AUTOSAR XML (schema 3.1.2)
package /Components/SWC_TqEM
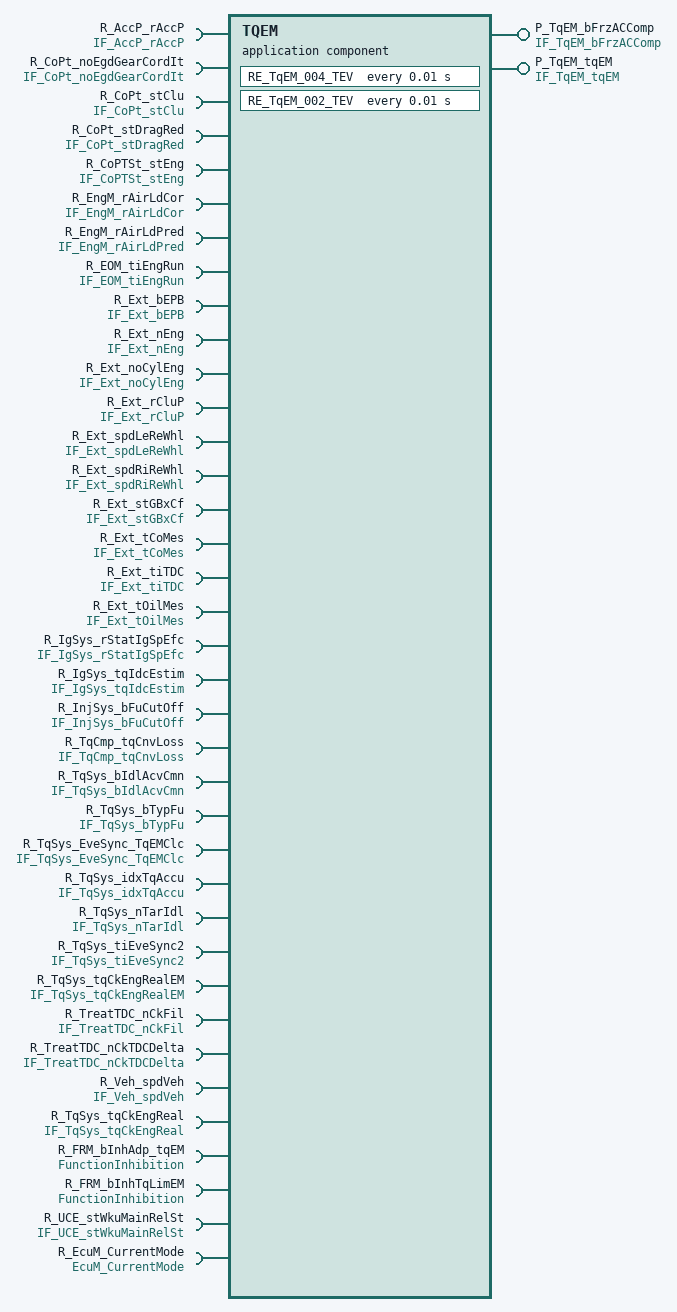
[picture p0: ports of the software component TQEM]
  application software component type TQEM
    35 x require port:
      R_AccP_rAccP: unqueued-receiver-com-spec{data-element=AccP_rAccP, init-value=ConstantValue, resync-time=0}, required-interface=IF_AccP_rAccP
      R_CoPt_noEgdGearCordIt: unqueued-receiver-com-spec{data-element=CoPt_noEgdGearCordIt, init-value=ConstantValue1, resync-time=0}, required-interface=IF_CoPt_noEgdGearCordIt
      R_CoPt_stClu: unqueued-receiver-com-spec{data-element=CoPt_stClu, init-value=CoPt_stClu_in, resync-time=0}, required-interface=IF_CoPt_stClu
      R_CoPt_stDragRed: unqueued-receiver-com-spec{data-element=CoPt_stDragRed, init-value=ConstantValue3, resync-time=0}, required-interface=IF_CoPt_stDragRed
      R_CoPTSt_stEng: unqueued-receiver-com-spec{data-element=CoPTSt_stEng, init-value=ConstantValue5, resync-time=0}, required-interface=IF_CoPTSt_stEng
      R_EngM_rAirLdCor: unqueued-receiver-com-spec{data-element=EngM_rAirLdCor, init-value=ConstantValue7, resync-time=0}, required-interface=IF_EngM_rAirLdCor
      R_EngM_rAirLdPred: unqueued-receiver-com-spec{data-element=EngM_rAirLdPred, init-value=ConstantValue9, resync-time=0}, required-interface=IF_EngM_rAirLdPred
      R_EOM_tiEngRun: unqueued-receiver-com-spec{data-element=EOM_tiEngRun, init-value=ConstantValue11, resync-time=0}, required-interface=IF_EOM_tiEngRun
      R_Ext_bEPB: unqueued-receiver-com-spec{data-element=Ext_bEPB, init-value=Ext_bEPB_in, resync-time=0}, required-interface=IF_Ext_bEPB
      R_Ext_nEng: unqueued-receiver-com-spec{data-element=Ext_nEng, init-value=ConstantValue13, resync-time=0}, required-interface=IF_Ext_nEng
      R_Ext_noCylEng: unqueued-receiver-com-spec{data-element=Ext_noCylEng, init-value=ConstantValue15, resync-time=0}, required-interface=IF_Ext_noCylEng
      R_Ext_rCluP: unqueued-receiver-com-spec{data-element=Ext_rCluP, init-value=Ext_rCluP_in, resync-time=0}, required-interface=IF_Ext_rCluP
      R_Ext_spdLeReWhl: unqueued-receiver-com-spec{data-element=Ext_spdLeReWhl, init-value=Ext_spdLeReWhl_in, resync-time=0}, required-interface=IF_Ext_spdLeReWhl
      R_Ext_spdRiReWhl: unqueued-receiver-com-spec{data-element=Ext_spdRiReWhl, init-value=Ext_spdRiReWhl_in, resync-time=0}, required-interface=IF_Ext_spdRiReWhl
      R_Ext_stGBxCf: unqueued-receiver-com-spec{data-element=Ext_stGBxCf, init-value=ConstantValue17, resync-time=0}, required-interface=IF_Ext_stGBxCf
      R_Ext_tCoMes: unqueued-receiver-com-spec{data-element=Ext_tCoMes, init-value=ConstantValue19, resync-time=0}, required-interface=IF_Ext_tCoMes
      R_Ext_tiTDC: unqueued-receiver-com-spec{data-element=Ext_tiTDC, init-value=ConstantValue21, resync-time=0}, required-interface=IF_Ext_tiTDC
      R_Ext_tOilMes: unqueued-receiver-com-spec{data-element=Ext_tOilMes, init-value=ConstantValue23, resync-time=0}, required-interface=IF_Ext_tOilMes
      R_IgSys_rStatIgSpEfc: unqueued-receiver-com-spec{data-element=IgSys_rStatIgSpEfc, init-value=ConstantValue25, resync-time=0}, required-interface=IF_IgSys_rStatIgSpEfc
      R_IgSys_tqIdcEstim: unqueued-receiver-com-spec{data-element=IgSys_tqIdcEstim, init-value=ConstantValue27, resync-time=0}, required-interface=IF_IgSys_tqIdcEstim
      R_InjSys_bFuCutOff: unqueued-receiver-com-spec{data-element=InjSys_bFuCutOff, init-value=ConstantValue29, resync-time=0}, required-interface=IF_InjSys_bFuCutOff
      R_TqCmp_tqCnvLoss: unqueued-receiver-com-spec{data-element=TqCmp_tqCnvLoss, init-value=ConstantValue31, resync-time=0}, required-interface=IF_TqCmp_tqCnvLoss
      R_TqSys_bIdlAcvCmn: unqueued-receiver-com-spec{data-element=TqSys_bIdlAcvCmn, init-value=ConstantValue33, resync-time=0}, required-interface=IF_TqSys_bIdlAcvCmn
      R_TqSys_bTypFu: unqueued-receiver-com-spec{data-element=TqSys_bTypFu, init-value=ConstantValue35, resync-time=0}, required-interface=IF_TqSys_bTypFu
      R_TqSys_EveSync_TqEMClc: unqueued-receiver-com-spec{data-element=TqSys_EveSync_TqEMClc, init-value=TqSys_EveSync_TqEMClc_in, resync-time=0}, required-interface=IF_TqSys_EveSync_TqEMClc
      R_TqSys_idxTqAccu: unqueued-receiver-com-spec{data-element=TqSys_idxTqAccu, init-value=ConstantValue37, resync-time=0}, required-interface=IF_TqSys_idxTqAccu
      R_TqSys_nTarIdl: unqueued-receiver-com-spec{data-element=TqSys_nTarIdl, init-value=ConstantValue39, resync-time=0}, required-interface=IF_TqSys_nTarIdl
      R_TqSys_tiEveSync2: unqueued-receiver-com-spec{data-element=TqSys_tiEveSync2, init-value=TqSys_tiEveSync2_in, resync-time=0}, required-interface=IF_TqSys_tiEveSync2
      R_TqSys_tqCkEngRealEM: unqueued-receiver-com-spec{data-element=TqSys_tqCkEngRealEM, init-value=ConstantValue41, resync-time=0}, required-interface=IF_TqSys_tqCkEngRealEM
      R_TreatTDC_nCkFil: unqueued-receiver-com-spec{data-element=TreatTDC_nCkFil, init-value=ConstantValue43, resync-time=0}, required-interface=IF_TreatTDC_nCkFil
      R_TreatTDC_nCkTDCDelta: unqueued-receiver-com-spec{data-element=TreatTDC_nCkTDCDelta, init-value=ConstantValue45, resync-time=0}, required-interface=IF_TreatTDC_nCkTDCDelta
      R_Veh_spdVeh: unqueued-receiver-com-spec{data-element=Veh_spdVeh, init-value=ConstantValue47, resync-time=0}, required-interface=IF_Veh_spdVeh
      R_TqSys_tqCkEngReal: unqueued-receiver-com-spec{data-element=TqSys_tqCkEngReal, init-value=ConstantValue49, resync-time=0}, required-interface=IF_TqSys_tqCkEngReal
      R_FRM_bInhAdp_tqEM: required-interface=FunctionInhibition
      R_FRM_bInhTqLimEM: required-interface=FunctionInhibition
    provide port P_TqEM_bFrzACComp: unqueued-sender-com-spec{data-element=TqEM_bFrzACComp, can-invalidate=false, init-value=ConstantValue51}, provided-interface=IF_TqEM_bFrzACComp
    provide port P_TqEM_tqEM: unqueued-sender-com-spec{data-element=TqEM_tqEM, can-invalidate=false, init-value=TqEM_tqEM_out}, provided-interface=IF_TqEM_tqEM
    require port R_UCE_stWkuMainRelSt: required-interface=IF_UCE_stWkuMainRelSt
    require port R_EcuM_CurrentMode: required-interface=EcuM_CurrentMode
  46 x constant specification:
    ConstantValue
      value:
        integer literal ConstantValue: type=DT_AccP_rAccP, value=0
    ConstantValue1
      value:
        integer literal ConstantValue1: type=DT_CoPt_noEgdGearCordIt, value=0
    ConstantValue11
      value:
        integer literal ConstantValue11: type=DT_EOM_tiEngRun, value=0
    ConstantValue13
      value:
        integer literal ConstantValue13: type=DT_Ext_nEng, value=0
    ConstantValue15
      value:
        integer literal ConstantValue15: type=DT_Ext_noCylEng, value=1
    ConstantValue17
      value:
        integer literal ConstantValue17: type=DT_Ext_stGBxCf, value=0
    ConstantValue19
      value:
        integer literal ConstantValue19: type=DT_Ext_tCoMes, value=20
    ConstantValue21
      value:
        integer literal ConstantValue21: type=DT_Ext_tiTDC, value=100
    ConstantValue23
      value:
        integer literal ConstantValue23: type=DT_Ext_tOilMes, value=0
    ConstantValue25
      value:
        integer literal ConstantValue25: type=DT_IgSys_rStatIgSpEfc, value=0
    ConstantValue27
      value:
        integer literal ConstantValue27: type=DT_IgSys_tqIdcEstim, value=0
    ConstantValue29
      value:
        boolean literal ConstantValue29: type=DT_InjSys_bFuCutOff, value=false
    ConstantValue3
      value:
        integer literal ConstantValue3: type=DT_CoPt_stDragRed, value=0
    ConstantValue31
      value:
        integer literal ConstantValue31: type=DT_TqCmp_tqCnvLoss, value=0
    ConstantValue33
      value:
        boolean literal ConstantValue33: type=DT_TqSys_bIdlAcvCmn, value=true
    ConstantValue35
      value:
        boolean literal ConstantValue35: type=DT_TqSys_bTypFu, value=false
    ConstantValue37
      value:
        integer literal ConstantValue37: type=DT_TqSys_idxTqAccu, value=1
    ConstantValue39
      value:
        integer literal ConstantValue39: type=DT_TqSys_nTarIdl, value=0
    ConstantValue41
      value:
        integer literal ConstantValue41: type=DT_TqSys_tqCkEngRealEM, value=0
    ConstantValue43
      value:
        integer literal ConstantValue43: type=DT_TreatTDC_nCkFil, value=0
    ConstantValue45
      value:
        integer literal ConstantValue45: type=DT_TreatTDC_nCkTDCDelta, value=0
    ConstantValue47
      value:
        integer literal ConstantValue47: type=DT_Veh_spdVeh, value=0
    ConstantValue49
      value:
        integer literal ConstantValue49: type=DT_TqSys_tqCkEngReal, value=0
    ConstantValue5
      value:
        integer literal ConstantValue5: type=DT_CoPTSt_stEng, value=1
    ConstantValue51
      value:
        boolean literal ConstantValue51: type=DT_TqEM_bFrzACComp, value=false
    ConstantValue7
      value:
        integer literal ConstantValue7: type=DT_EngM_rAirLdCor, value=0
    ConstantValue9
      value:
        integer literal ConstantValue9: type=DT_EngM_rAirLdPred, value=0
    CoPt_stClu_in
      value:
        integer literal CoPt_stClu_in: type=DT_CoPt_stClu, value=0
    Ext_bEPB_in
      value:
        boolean literal Ext_bEPB_in: type=DT_Ext_bEPB, value=false
    Ext_rCluP_in
      value:
        integer literal Ext_rCluP_in: type=DT_Ext_rCluP, value=0
    Ext_spdLeReWhl_in
      value:
        integer literal Ext_spdLeReWhl_in: type=DT_Ext_spdLeReWhl, value=0
    Ext_spdRiReWhl_in
      value:
        integer literal Ext_spdRiReWhl_in: type=DT_Ext_spdRiReWhl, value=0
    TqEM_bAuthClc_Cst
      value:
        boolean literal TqEM_bAuthClc_Cst: type=DT_TqEM_bAuthClc, value=false
    TqEM_bEnaAvr3Sync_Cst
      value:
        boolean literal TqEM_bEnaAvr3Sync_Cst: type=DT_TqEM_bEnaAvr3Sync, value=false
    TqEM_bEnaAvr4Sync_Cst
      value:
        boolean literal TqEM_bEnaAvr4Sync_Cst: type=DT_TqEM_bEnaAvr4Sync, value=false
    TqEM_bEnaAvr6Sync_Cst
      value:
        boolean literal TqEM_bEnaAvr6Sync_Cst: type=DT_TqEM_bEnaAvr6Sync, value=false
    TqEM_EveSync_Cst
      value:
        boolean literal TqEM_EveSync_Cst: type=DT_TqEM_EveSync, value=false
    TqEM_facTEng_Cst
      value:
        integer literal TqEM_facTEng_Cst: type=DT_TqEM_facTEng, value=40
    TqEM_tiEveSync_Cst
      value:
        integer literal TqEM_tiEveSync_Cst: type=DT_TqEM_tiEveSync, value=0
    TqEM_tqAdp_Cst
      value:
        integer literal TqEM_tqAdp_Cst: type=DT_TqEM_tqAdp, value=0
    TqEM_tqAdpRaw_Cst
      value:
        integer literal TqEM_tqAdpRaw_Cst: type=DT_TqEM_tqAdpRaw, value=0
    TqEM_tqCkEngRealEM_Cst
      value:
        integer literal TqEM_tqCkEngRealEM_Cst: type=DT_TqEM_tqCkEngRealEM, value=0
    TqEM_tqEM_out
      value:
        integer literal TqEM_tqEM_out: type=DT_TqEM_tqEM, value=0
    TqEM_tqEMWiCutOff_Cst
      value:
        integer literal TqEM_tqEMWiCutOff_Cst: type=DT_TqEM_tqEMWiCutOff, value=0
    TqSys_EveSync_TqEMClc_in
      value:
        boolean literal TqSys_EveSync_TqEMClc_in: type=DT_TqSys_EveSync_TqEMClc, value=false
    TqSys_tiEveSync2_in
      value:
        integer literal TqSys_tiEveSync2_in: type=DT_TqSys_tiEveSync2, value=0
  internal behavior IB_TqEM: component=TQEM
    mode switch event EV_TqEM_001_MSE: start-on-event=RE_TqEM_001_MSE, activation=ENTRY, mode=R_EcuM_CurrentMode.currentMode.RUN
    timing event EV_TqEM_004_TEV: mode-dependency=dependent-on-mode=[R_UCE_stWkuMainRelSt.RCD_stWkuMainRelSt.PreMainWakeUp, R_UCE_stWkuMainRelSt.RCD_stWkuMainRelSt.PostMainWakeUp, R_UCE_stWkuMainRelSt.RCD_stWkuMainRelSt.Invalid], start-on-event=RE_TqEM_004_TEV, period=0.01
    data received event EV_TqEM_006_DRE: mode-dependency=dependent-on-mode=[R_UCE_stWkuMainRelSt.RCD_stWkuMainRelSt.PreMainWakeUp, R_UCE_stWkuMainRelSt.RCD_stWkuMainRelSt.PostMainWakeUp, R_UCE_stWkuMainRelSt.RCD_stWkuMainRelSt.Invalid], start-on-event=RE_TqEM_006_DRE, data=R_TqSys_EveSync_TqEMClc.TqSys_EveSync_TqEMClc
    timing event EV_TqEM_002_TEV: mode-dependency=dependent-on-mode=[R_UCE_stWkuMainRelSt.RCD_stWkuMainRelSt.PreMainWakeUp, R_UCE_stWkuMainRelSt.RCD_stWkuMainRelSt.PostMainWakeUp, R_UCE_stWkuMainRelSt.RCD_stWkuMainRelSt.Invalid], start-on-event=RE_TqEM_002_TEV, period=0.01
    11 x inter runnable variable, all with sw-calibration-access=READ-WRITE, communication-approach=EXPLICIT:
      TqEM_facTEng: type=DT_TqEM_facTEng, init-value=TqEM_facTEng_Cst
      TqEM_tqCkEngRealEM: type=DT_TqEM_tqCkEngRealEM, init-value=TqEM_tqCkEngRealEM_Cst
      TqEM_bAuthClc: type=DT_TqEM_bAuthClc, init-value=TqEM_bAuthClc_Cst
      TqEM_tqAdpRaw: type=DT_TqEM_tqAdpRaw, init-value=TqEM_tqAdpRaw_Cst
      TqEM_bEnaAvr3Sync: type=DT_TqEM_bEnaAvr3Sync, init-value=TqEM_bEnaAvr3Sync_Cst
      TqEM_bEnaAvr6Sync: type=DT_TqEM_bEnaAvr6Sync, init-value=TqEM_bEnaAvr6Sync_Cst
      TqEM_tiEveSync: type=DT_TqEM_tiEveSync, init-value=TqEM_tiEveSync_Cst
      TqEM_EveSync: type=DT_TqEM_EveSync, init-value=TqEM_EveSync_Cst
      TqEM_bEnaAvr4Sync: type=DT_TqEM_bEnaAvr4Sync, init-value=TqEM_bEnaAvr4Sync_Cst
      TqEM_tqEMWiCutOff: type=DT_TqEM_tqEMWiCutOff, init-value=TqEM_tqEMWiCutOff_Cst
      TqEM_tqAdp: type=DT_TqEM_tqAdp, init-value=TqEM_tqAdp_Cst
    4 x runnable:
      RE_TqEM_006_DRE: read-variable=[TqEM_bAuthClc, TqEM_facTEng, TqEM_EveSync, TqEM_tqAdp, TqEM_tiEveSync, TqEM_tqCkEngRealEM], written-variable=[TqEM_bEnaAvr6Sync, TqEM_tqEMWiCutOff, TqEM_tqAdpRaw, TqEM_bEnaAvr3Sync, TqEM_bEnaAvr4Sync]
        16 x data receive point:
          dr_TqSys_bTypFu: data-element=R_TqSys_bTypFu.TqSys_bTypFu
          dr_TqSys_idxTqAccu: data-element=R_TqSys_idxTqAccu.TqSys_idxTqAccu
          dr_TreatTDC_nCkFil: data-element=R_TreatTDC_nCkFil.TreatTDC_nCkFil
          dr_TreatTDC_nCkTDCDelta: data-element=R_TreatTDC_nCkTDCDelta.TreatTDC_nCkTDCDelta
          dr_Ext_tCoMes: data-element=R_Ext_tCoMes.Ext_tCoMes
          dr_AccP_rAccP: data-element=R_AccP_rAccP.AccP_rAccP
          dr_IgSys_rStatIgSpEfc: data-element=R_IgSys_rStatIgSpEfc.IgSys_rStatIgSpEfc
          dr_EngM_rAirLdCor: data-element=R_EngM_rAirLdCor.EngM_rAirLdCor
          dr_TqSys_nTarIdl: data-element=R_TqSys_nTarIdl.TqSys_nTarIdl
          dr_InjSys_bFuCutOff: data-element=R_InjSys_bFuCutOff.InjSys_bFuCutOff
          dr_EngM_rAirLdPred: data-element=R_EngM_rAirLdPred.EngM_rAirLdPred
          dr_EOM_tiEngRun: data-element=R_EOM_tiEngRun.EOM_tiEngRun
          dr_IgSys_tqIdcEstim: data-element=R_IgSys_tqIdcEstim.IgSys_tqIdcEstim
          dr_TqCmp_tqCnvLoss: data-element=R_TqCmp_tqCnvLoss.TqCmp_tqCnvLoss
          dr_Ext_nEng: data-element=R_Ext_nEng.Ext_nEng
          dr_Ext_noCylEng: data-element=R_Ext_noCylEng.Ext_noCylEng
      RE_TqEM_004_TEV: read-variable=[TqEM_tqAdpRaw, TqEM_bEnaAvr6Sync, TqEM_tqCkEngRealEM, TqEM_tqEMWiCutOff, TqEM_bEnaAvr4Sync, TqEM_bEnaAvr3Sync], written-variable=[TqEM_bAuthClc, TqEM_tqAdp, TqEM_facTEng]
        16 x data receive point:
          dr_CoPt_noEgdGearCordIt: data-element=R_CoPt_noEgdGearCordIt.CoPt_noEgdGearCordIt
          dr_Ext_nEng: data-element=R_Ext_nEng.Ext_nEng
          dr_Ext_tCoMes: data-element=R_Ext_tCoMes.Ext_tCoMes
          dr_CoPt_stDragRed: data-element=R_CoPt_stDragRed.CoPt_stDragRed
          dr_CoPTSt_stEng: data-element=R_CoPTSt_stEng.CoPTSt_stEng
          dr_TqSys_nTarIdl: data-element=R_TqSys_nTarIdl.TqSys_nTarIdl
          dr_CoPt_stClu: data-element=R_CoPt_stClu.CoPt_stClu
          dr_Ext_rCluP: data-element=R_Ext_rCluP.Ext_rCluP
          dr_Ext_tOilMes: data-element=R_Ext_tOilMes.Ext_tOilMes
          dr_Ext_stGBxCf: data-element=R_Ext_stGBxCf.Ext_stGBxCf
          dr_Ext_bEPB: data-element=R_Ext_bEPB.Ext_bEPB
          dr_AccP_rAccP: data-element=R_AccP_rAccP.AccP_rAccP
          dr_TqSys_bIdlAcvCmn: data-element=R_TqSys_bIdlAcvCmn.TqSys_bIdlAcvCmn
          dr_Ext_spdLeReWhl: data-element=R_Ext_spdLeReWhl.Ext_spdLeReWhl
          dr_Ext_spdRiReWhl: data-element=R_Ext_spdRiReWhl.Ext_spdRiReWhl
          dr_Veh_spdVeh: data-element=R_Veh_spdVeh.Veh_spdVeh
        data send point ds_TqEM_tqEM: data-element=P_TqEM_tqEM.TqEM_tqEM
        data send point ds_TqEM_bFrzACComp: data-element=P_TqEM_bFrzACComp.TqEM_bFrzACComp
        sync call ssp_FRM_bInhTqLimEM: operation=R_FRM_bInhTqLimEM.GetFunctionPermission
        sync call ssp_FRM_bInhAdp_tqEM: operation=R_FRM_bInhAdp_tqEM.GetFunctionPermission
      RE_TqEM_002_TEV: written-variable=[TqEM_tqCkEngRealEM, TqEM_EveSync, TqEM_tiEveSync]
        6 x data receive point:
          dr_TqSys_bTypFu: data-element=R_TqSys_bTypFu.TqSys_bTypFu
          dr_TqSys_tqCkEngRealEM: data-element=R_TqSys_tqCkEngRealEM.TqSys_tqCkEngRealEM
          dr_Ext_tiTDC: data-element=R_Ext_tiTDC.Ext_tiTDC
          dr_Ext_nEng: data-element=R_Ext_nEng.Ext_nEng
          dr_TqSys_tqCkEngReal: data-element=R_TqSys_tqCkEngReal.TqSys_tqCkEngReal
          dr_TqSys_tiEveSync2: data-element=R_TqSys_tiEveSync2.TqSys_tiEveSync2
      RE_TqEM_001_MSE: written-variable=[TqEM_bEnaAvr4Sync, TqEM_tiEveSync, TqEM_facTEng, TqEM_tqAdpRaw, TqEM_tqEMWiCutOff, TqEM_EveSync, TqEM_tqAdp, TqEM_bEnaAvr6Sync, TqEM_bAuthClc, TqEM_tqCkEngRealEM, TqEM_bEnaAvr3Sync]
        data send point ds_TqEM_bFrzACComp: data-element=P_TqEM_bFrzACComp.TqEM_bFrzACComp
        data send point ds_TqEM_tqEM: data-element=P_TqEM_tqEM.TqEM_tqEM
  swc implementation Imp_TqEM: programming-language=C, behavior=IB_TqEM
    code-descriptors:
      code CodeDescriptor: type=SRC
        17 x xfile:
          TqEM_004_calibrations_c: url=TqEM_004_calibrations.c
          TqEM_006_DRE_fct_h: url=TqEM_006_DRE_fct.h
          TqEM_004_calibrations_h: url=TqEM_004_calibrations.h
          TqEM_006_DRE_fct_c: url=TqEM_006_DRE_fct.c
          TqEM_002_TEV_fct_h: url=TqEM_002_TEV_fct.h
          TqEM_MemMap_h: url=TqEM_MemMap.h
          TqEM_006_lut_c: url=TqEM_006_lut.c
          TqEM_c: url=TqEM.c
          TqEM_004_TEV_fct_c: url=TqEM_004_TEV_fct.c
          TqEM_006_calibrations_c: url=TqEM_006_calibrations.c
          TqEM_002_calibrations_h: url=TqEM_002_calibrations.h
          TqEM_006_calibrations_h: url=TqEM_006_calibrations.h
          TqEM_h: url=TqEM.h
          TqEM_002_calibrations_c: url=TqEM_002_calibrations.c
          TqEM_004_TEV_fct_h: url=TqEM_004_TEV_fct.h
          TqEM_006_lut_h: url=TqEM_006_lut.h
          TqEM_002_TEV_fct_c: url=TqEM_002_TEV_fct.c
package /Components/SWC_TqEM/TqEM_IRVDatatypes
  5 x boolean type, all with base-type=boolean:
    DT_TqEM_bAuthClc
    DT_TqEM_bEnaAvr3Sync
    DT_TqEM_bEnaAvr4Sync
    DT_TqEM_bEnaAvr6Sync
    DT_TqEM_EveSync
  6 x integer type:
    DT_TqEM_facTEng: base-type=int16, lower-limit=-32768, upper-limit=32767
    DT_TqEM_tiEveSync: base-type=uint8, lower-limit=0, upper-limit=255
    DT_TqEM_tqAdp: base-type=int16, lower-limit=-32768, upper-limit=32767
    DT_TqEM_tqAdpRaw: base-type=int16, lower-limit=-32768, upper-limit=32767
    DT_TqEM_tqCkEngRealEM: base-type=int16, lower-limit=-32768, upper-limit=32767
    DT_TqEM_tqEMWiCutOff: base-type=int16, lower-limit=-32768, upper-limit=32767
